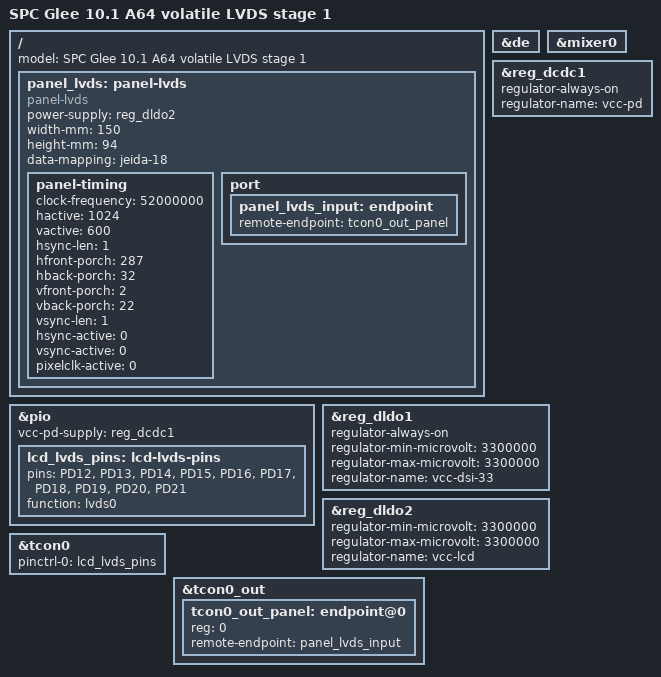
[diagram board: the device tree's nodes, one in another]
// SPDX-License-Identifier: (GPL-2.0+ OR MIT)

#include "sun50i-a64-spc-glee-volatile.dts"
#include <dt-bindings/gpio/gpio.h>

/ {
	model = "SPC Glee 10.1 A64 volatile LVDS stage 1";

	panel_lvds: panel-lvds {
		compatible = "panel-lvds";
		power-supply = <&reg_dldo2>;

		width-mm = <150>;
		height-mm = <94>;
		data-mapping = "jeida-18";

		panel-timing {
			/* Converted from the vendor BSP totals: 1344 x 625 at 52 MHz. */
			clock-frequency = <52000000>;
			hactive = <1024>;
			vactive = <600>;
			hsync-len = <1>;
			hfront-porch = <287>;
			hback-porch = <32>;
			vfront-porch = <2>;
			vback-porch = <22>;
			vsync-len = <1>;
			hsync-active = <0>;
			vsync-active = <0>;
			pixelclk-active = <0>;
		};

		port {
			panel_lvds_input: endpoint {
				remote-endpoint = <&tcon0_out_panel>;
			};
		};
	};
};

&de {
	status = "okay";
};

&mixer0 {
	status = "okay";
};

&pio {
	vcc-pd-supply = <&reg_dcdc1>;

	lcd_lvds_pins: lcd-lvds-pins {
		pins = "PD12", "PD13", "PD14", "PD15", "PD16",
		       "PD17", "PD18", "PD19", "PD20", "PD21";
		function = "lvds0";
	};
};

&reg_dcdc1 {
	regulator-always-on;
	regulator-name = "vcc-pd";
};

&reg_dldo1 {
	regulator-always-on;
	regulator-min-microvolt = <3300000>;
	regulator-max-microvolt = <3300000>;
	regulator-name = "vcc-dsi-33";
};

&reg_dldo2 {
	regulator-min-microvolt = <3300000>;
	regulator-max-microvolt = <3300000>;
	regulator-name = "vcc-lcd";
};

&tcon0 {
	pinctrl-names = "default";
	pinctrl-0 = <&lcd_lvds_pins>;
	status = "okay";
};

&tcon0_out {
	tcon0_out_panel: endpoint@0 {
		reg = <0>;
		remote-endpoint = <&panel_lvds_input>;
	};
};
